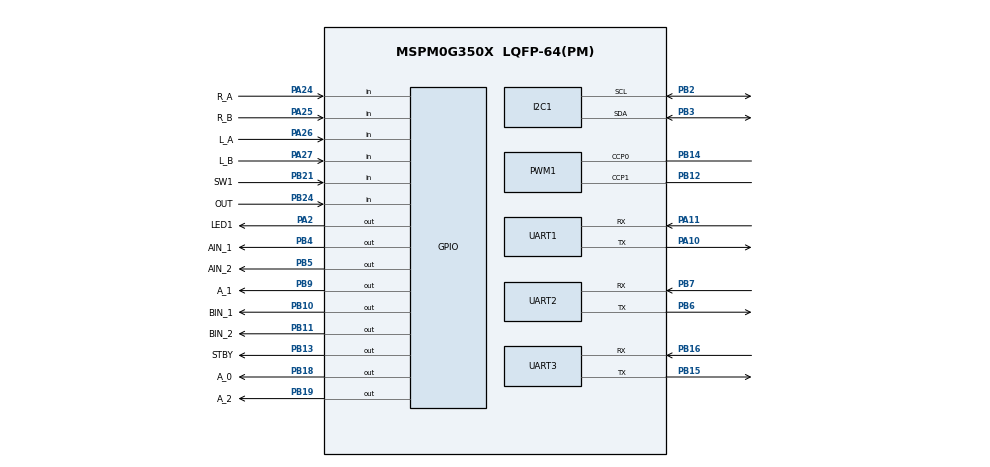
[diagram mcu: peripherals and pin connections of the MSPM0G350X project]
/**
 * @cliArgs --device "MSPM0G350X" --part "Default" --package "LQFP-64(PM)" --product "mspm0_sdk@2.11.00.07"
 * @versions {"tool":"1.26.2+4477"}
 */

/**
 * Import the modules used in this configuration.
 */
const GPIO   = scripting.addModule("/ti/driverlib/GPIO", {}, false);
const GPIO1  = GPIO.addInstance();
const GPIO2  = GPIO.addInstance();
const GPIO3  = GPIO.addInstance();
const GPIO4  = GPIO.addInstance();
const GPIO5  = GPIO.addInstance();
const I2C    = scripting.addModule("/ti/driverlib/I2C", {}, false);
const I2C1   = I2C.addInstance();
const PWM    = scripting.addModule("/ti/driverlib/PWM", {}, false);
const PWM1   = PWM.addInstance();
const SYSCTL = scripting.addModule("/ti/driverlib/SYSCTL");
const UART   = scripting.addModule("/ti/driverlib/UART", {}, false);
const UART1  = UART.addInstance();
const UART2  = UART.addInstance();
const UART3  = UART.addInstance();

/**
 * Write custom configuration values to the imported modules.
 */
GPIO1.$name                         = "LED";
GPIO1.port                          = "PORTA";
GPIO1.associatedPins[0].$name       = "LED1";
GPIO1.associatedPins[0].pin.$assign = "PA2";

const Board = scripting.addModule("/ti/driverlib/Board", {}, false);

GPIO2.$name                              = "KEY";
GPIO2.port                               = "PORTB";
GPIO2.associatedPins[0].$name            = "SW1";
GPIO2.associatedPins[0].direction        = "INPUT";
GPIO2.associatedPins[0].internalResistor = "PULL_UP";
GPIO2.associatedPins[0].interruptEn      = true;
GPIO2.associatedPins[0].polarity         = "FALL";
GPIO2.associatedPins[0].pin.$assign      = "PB21";

GPIO3.$name                         = "GPIO_MOTOR_DIR";
GPIO3.port                          = "PORTB";
GPIO3.associatedPins.create(5);
GPIO3.associatedPins[0].$name       = "AIN_1";
GPIO3.associatedPins[0].pin.$assign = "PB4";
GPIO3.associatedPins[1].$name       = "AIN_2";
GPIO3.associatedPins[1].pin.$assign = "PB5";
GPIO3.associatedPins[2].$name       = "BIN_1";
GPIO3.associatedPins[2].pin.$assign = "PB10";
GPIO3.associatedPins[3].$name       = "BIN_2";
GPIO3.associatedPins[3].pin.$assign = "PB11";
GPIO3.associatedPins[4].$name       = "STBY";
GPIO3.associatedPins[4].pin.$assign = "PB13";

GPIO4.$name                         = "GRAY";
GPIO4.port                          = "PORTB";
GPIO4.associatedPins.create(4);
GPIO4.associatedPins[0].$name       = "A_0";
GPIO4.associatedPins[0].pin.$assign = "PB18";
GPIO4.associatedPins[1].$name       = "A_1";
GPIO4.associatedPins[1].pin.$assign = "PB9";
GPIO4.associatedPins[2].$name       = "A_2";
GPIO4.associatedPins[2].pin.$assign = "PB19";
GPIO4.associatedPins[3].$name       = "OUT";
GPIO4.associatedPins[3].direction   = "INPUT";
GPIO4.associatedPins[3].pin.$assign = "PB24";

GPIO5.$name                               = "ENC";
GPIO5.port                                = "PORTA";
GPIO5.associatedPins.create(4);
GPIO5.associatedPins[0].$name             = "L_A";
GPIO5.associatedPins[0].direction         = "INPUT";
GPIO5.associatedPins[0].internalResistor  = "PULL_UP";
GPIO5.associatedPins[0].interruptEn       = true;
GPIO5.associatedPins[0].polarity          = "RISE_FALL";
GPIO5.associatedPins[0].interruptPriority = "0";
GPIO5.associatedPins[0].pin.$assign       = "PA26";
GPIO5.associatedPins[1].$name             = "L_B";
GPIO5.associatedPins[1].direction         = "INPUT";
GPIO5.associatedPins[1].internalResistor  = "PULL_UP";
GPIO5.associatedPins[1].interruptEn       = true;
GPIO5.associatedPins[1].polarity          = "RISE_FALL";
GPIO5.associatedPins[1].interruptPriority = "0";
GPIO5.associatedPins[1].pin.$assign       = "PA27";
GPIO5.associatedPins[2].$name             = "R_A";
GPIO5.associatedPins[2].direction         = "INPUT";
GPIO5.associatedPins[2].internalResistor  = "PULL_UP";
GPIO5.associatedPins[2].interruptEn       = true;
GPIO5.associatedPins[2].polarity          = "RISE_FALL";
GPIO5.associatedPins[2].interruptPriority = "0";
GPIO5.associatedPins[2].pin.$assign       = "PA24";
GPIO5.associatedPins[3].$name             = "R_B";
GPIO5.associatedPins[3].direction         = "INPUT";
GPIO5.associatedPins[3].internalResistor  = "PULL_UP";
GPIO5.associatedPins[3].interruptEn       = true;
GPIO5.associatedPins[3].polarity          = "RISE_FALL";
GPIO5.associatedPins[3].interruptPriority = "0";
GPIO5.associatedPins[3].pin.$assign       = "PA25";

I2C1.$name                             = "I2C_OLED";
I2C1.basicEnableController             = true;
I2C1.basicTargetAddress                = 0x3C;
I2C1.basicClockSourceDivider           = 4;
I2C1.peripheral.$assign                = "I2C1";
I2C1.peripheral.sdaPin.$assign         = "PB3";
I2C1.peripheral.sclPin.$assign         = "PB2";
I2C1.sdaPinConfig.hideOutputInversion  = scripting.forceWrite(false);
I2C1.sdaPinConfig.onlyInternalResistor = scripting.forceWrite(false);
I2C1.sdaPinConfig.passedPeripheralType = scripting.forceWrite("Digital");
I2C1.sdaPinConfig.$name                = "ti_driverlib_gpio_GPIOPinGeneric6";
I2C1.sdaPinConfig.enableConfig         = true;
I2C1.sdaPinConfig.internalResistor     = "PULL_UP";
I2C1.sclPinConfig.hideOutputInversion  = scripting.forceWrite(false);
I2C1.sclPinConfig.onlyInternalResistor = scripting.forceWrite(false);
I2C1.sclPinConfig.passedPeripheralType = scripting.forceWrite("Digital");
I2C1.sclPinConfig.$name                = "ti_driverlib_gpio_GPIOPinGeneric7";
I2C1.sclPinConfig.enableConfig         = true;
I2C1.sclPinConfig.internalResistor     = "PULL_UP";

PWM1.clockDivider                       = 1;
PWM1.$name                              = "MOTOR_PWM";
PWM1.timerCount                         = 1600;
PWM1.pwmMode                            = "EDGE_ALIGN_UP";
PWM1.peripheral.$assign                 = "TIMA0";
PWM1.peripheral.ccp0Pin.$assign         = "PB14";
PWM1.peripheral.ccp1Pin.$assign         = "PB12";
PWM1.PWM_CHANNEL_0.$name                = "ti_driverlib_pwm_PWMTimerCC0";
PWM1.PWM_CHANNEL_1.$name                = "ti_driverlib_pwm_PWMTimerCC1";
PWM1.ccp0PinConfig.direction            = scripting.forceWrite("OUTPUT");
PWM1.ccp0PinConfig.hideOutputInversion  = scripting.forceWrite(false);
PWM1.ccp0PinConfig.onlyInternalResistor = scripting.forceWrite(false);
PWM1.ccp0PinConfig.passedPeripheralType = scripting.forceWrite("Digital");
PWM1.ccp0PinConfig.$name                = "ti_driverlib_gpio_GPIOPinGeneric8";
PWM1.ccp1PinConfig.direction            = scripting.forceWrite("OUTPUT");
PWM1.ccp1PinConfig.hideOutputInversion  = scripting.forceWrite(false);
PWM1.ccp1PinConfig.onlyInternalResistor = scripting.forceWrite(false);
PWM1.ccp1PinConfig.passedPeripheralType = scripting.forceWrite("Digital");
PWM1.ccp1PinConfig.$name                = "ti_driverlib_gpio_GPIOPinGeneric9";

SYSCTL.forceDefaultClkConfig = true;

UART1.targetBaudRate                   = 115200;
UART1.$name                            = "UART_TEST";
UART1.enabledInterrupts                = ["RX"];
UART1.interruptPriority                = "2";
UART1.peripheral.$assign               = "UART0";
UART1.peripheral.rxPin.$assign         = "PA11";
UART1.peripheral.txPin.$assign         = "PA10";
UART1.txPinConfig.direction            = scripting.forceWrite("OUTPUT");
UART1.txPinConfig.hideOutputInversion  = scripting.forceWrite(false);
UART1.txPinConfig.onlyInternalResistor = scripting.forceWrite(false);
UART1.txPinConfig.passedPeripheralType = scripting.forceWrite("Digital");
UART1.txPinConfig.$name                = "ti_driverlib_gpio_GPIOPinGeneric0";
UART1.rxPinConfig.hideOutputInversion  = scripting.forceWrite(false);
UART1.rxPinConfig.onlyInternalResistor = scripting.forceWrite(false);
UART1.rxPinConfig.passedPeripheralType = scripting.forceWrite("Digital");
UART1.rxPinConfig.$name                = "ti_driverlib_gpio_GPIOPinGeneric1";

UART2.$name                            = "UART_CAMARE";
UART2.targetBaudRate                   = 115200;
UART2.enabledInterrupts                = ["RX"];
UART2.interruptPriority                = "2";
UART2.peripheral.$assign               = "UART1";
UART2.peripheral.rxPin.$assign         = "PB7";
UART2.peripheral.txPin.$assign         = "PB6";
UART2.txPinConfig.direction            = scripting.forceWrite("OUTPUT");
UART2.txPinConfig.hideOutputInversion  = scripting.forceWrite(false);
UART2.txPinConfig.onlyInternalResistor = scripting.forceWrite(false);
UART2.txPinConfig.passedPeripheralType = scripting.forceWrite("Digital");
UART2.txPinConfig.$name                = "ti_driverlib_gpio_GPIOPinGeneric2";
UART2.rxPinConfig.hideOutputInversion  = scripting.forceWrite(false);
UART2.rxPinConfig.onlyInternalResistor = scripting.forceWrite(false);
UART2.rxPinConfig.passedPeripheralType = scripting.forceWrite("Digital");
UART2.rxPinConfig.$name                = "ti_driverlib_gpio_GPIOPinGeneric3";

UART3.$name                            = "UART_GIMBAL";
UART3.targetBaudRate                   = 115200;
UART3.enabledInterrupts                = ["RX"];
UART3.interruptPriority                = "2";
UART3.peripheral.rxPin.$assign         = "PB16";
UART3.peripheral.txPin.$assign         = "PB15";
UART3.txPinConfig.direction            = scripting.forceWrite("OUTPUT");
UART3.txPinConfig.hideOutputInversion  = scripting.forceWrite(false);
UART3.txPinConfig.onlyInternalResistor = scripting.forceWrite(false);
UART3.txPinConfig.passedPeripheralType = scripting.forceWrite("Digital");
UART3.txPinConfig.$name                = "ti_driverlib_gpio_GPIOPinGeneric4";
UART3.rxPinConfig.hideOutputInversion  = scripting.forceWrite(false);
UART3.rxPinConfig.onlyInternalResistor = scripting.forceWrite(false);
UART3.rxPinConfig.passedPeripheralType = scripting.forceWrite("Digital");
UART3.rxPinConfig.$name                = "ti_driverlib_gpio_GPIOPinGeneric5";

/**
 * Pinmux solution for unlocked pins/peripherals. This ensures that minor changes to the automatic solver in a future
 * version of the tool will not impact the pinmux you originally saw.  These lines can be completely deleted in order to
 * re-solve from scratch.
 */
Board.peripheral.$suggestSolution          = "DEBUGSS";
Board.peripheral.swclkPin.$suggestSolution = "PA20";
Board.peripheral.swdioPin.$suggestSolution = "PA19";
SYSCTL.peripheral.$suggestSolution         = "SYSCTL";
UART3.peripheral.$suggestSolution          = "UART2";
